# STM32L552xx register map
File version: 1.0
Registers are 32-bit, read-write, reset 0x0 unless marked. A register's access mark holds for its fields unless they carry their own. Offsets are from the block's base; [hi:lo] are bit positions; lines under a group give offsets from that group; {n}, {i} and the like mark numbered series.

## TSC — Touch Sensing Controller (TSC)
Base 0x40024000
Same registers: TSC_S 0x50024000
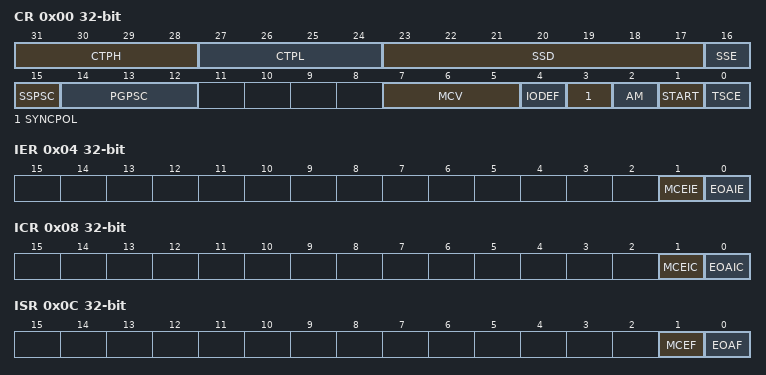
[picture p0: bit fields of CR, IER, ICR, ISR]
0x00 CR — TSC control register
  [31:28] CTPH — CTPH[3:0] bits (Charge Transfer pulse high)
  [27:24] CTPL — CTPL[3:0] bits (Charge Transfer pulse low)
  [23:17] SSD — SSD[6:0] bits (Spread Spectrum Deviation)
  [16] SSE — Spread Spectrum Enable
  [15] SSPSC — Spread Spectrum Prescaler
  [14:12] PGPSC — PGPSC[2:0] bits (Pulse Generator Prescaler)
  [7:5] MCV — MCV[2:0] bits (Max Count Value)
  [4] IODEF — IO default mode
  [3] SYNCPOL — Synchronization pin polarity
  [2] AM — Acquisition mode
  [1] START — Start acquisition
  [0] TSCE — Touch sensing controller enable
0x04 IER — TSC interrupt enable register
  [1] MCEIE — Max count error interrupt enable
  [0] EOAIE — End of acquisition interrupt enable
0x08 ICR — TSC interrupt clear register
  [1] MCEIC — Max count error interrupt clear
  [0] EOAIC — End of acquisition interrupt clear
0x0C ISR — TSC interrupt status register
  [1] MCEF — Max count error flag
  [0] EOAF — End of acquisition flag
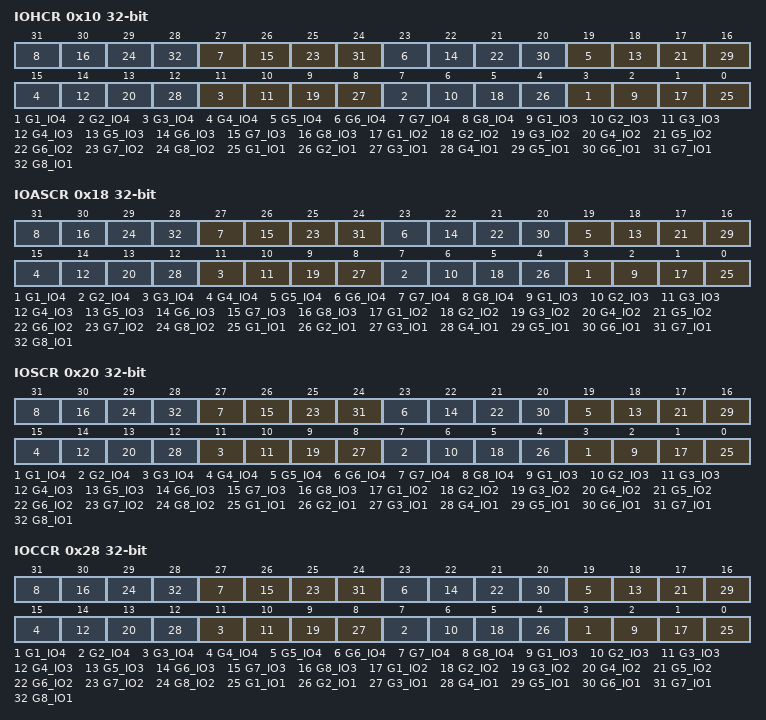
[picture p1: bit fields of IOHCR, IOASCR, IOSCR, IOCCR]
0x10 IOHCR — TSC I/O hysteresis control register
  [4n-1] G{n}_IO4 (n=1..8) — GROUP{n}_IO4 schmitt trigger hysteresis mode
  [4n-2] G{n}_IO3 (n=1..8) — GROUP{n}_IO3 schmitt trigger hysteresis mode
  [4n-3] G{n}_IO2 (n=1..8) — GROUP{n}_IO2 schmitt trigger hysteresis mode
  [4n-4] G{n}_IO1 (n=1..8) — GROUP{n}_IO1 schmitt trigger hysteresis mode
0x18 IOASCR — TSC I/O analog switch control register
  [4n-1] G{n}_IO4 (n=1..8) — GROUP{n}_IO4 analog switch enable
  [4n-2] G{n}_IO3 (n=1..8) — GROUP{n}_IO3 analog switch enable
  [4n-3] G{n}_IO2 (n=1..8) — GROUP{n}_IO2 analog switch enable
  [4n-4] G{n}_IO1 (n=1..8) — GROUP{n}_IO1 analog switch enable
0x20 IOSCR — TSC I/O sampling control register
  [4n-1] G{n}_IO4 (n=1..8) — GROUP{n}_IO4 sampling mode
  [4n-2] G{n}_IO3 (n=1..8) — GROUP{n}_IO3 sampling mode
  [4n-3] G{n}_IO2 (n=1..8) — GROUP{n}_IO2 sampling mode
  [4n-4] G{n}_IO1 (n=1..8) — GROUP{n}_IO1 sampling mode
0x28 IOCCR — TSC I/O channel control register
  [4n-1] G{n}_IO4 (n=1..8) — GROUP{n}_IO4 channel mode
  [4n-2] G{n}_IO3 (n=1..8) — GROUP{n}_IO3 channel mode
  [4n-3] G{n}_IO2 (n=1..8) — GROUP{n}_IO2 channel mode
  [4n-4] G{n}_IO1 (n=1..8) — GROUP{n}_IO1 channel mode
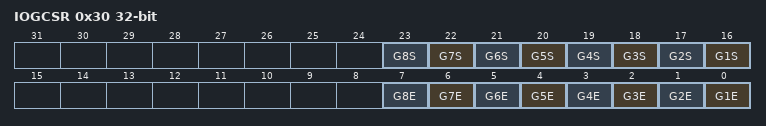
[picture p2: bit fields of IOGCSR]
0x30 IOGCSR — TSC I/O group control status register
  [n+15] G{n}S (n=1..8) — Analog IO GROUP{n} status
  [n-1] G{n}E (n=1..8) — Analog IO GROUP{n} enable
{0x30+4i} IOG{i}CR (i=1..8) — TSC I/O group x counter register
  [13:0] CNT — CNT[13:0] bits (Counter value)

## EXTI — Asynch Interrupt/Event Controller (EXTI)
Base 0x4002F400
Same registers: EXTI_S 0x5002F400
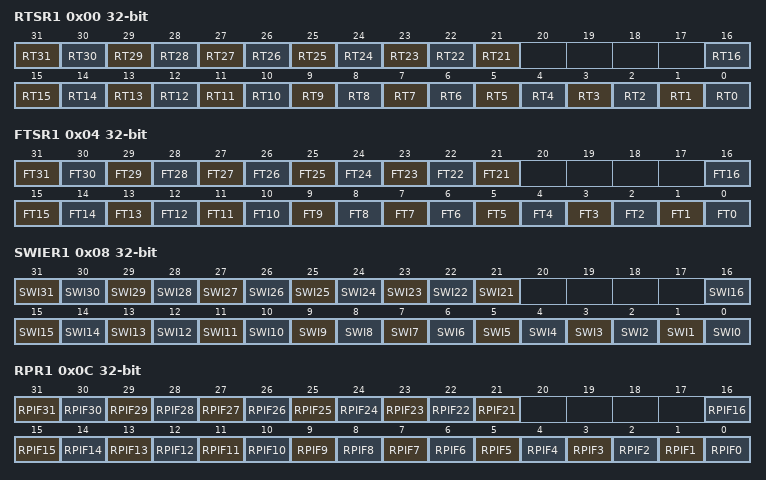
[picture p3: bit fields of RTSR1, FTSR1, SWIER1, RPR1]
0x00 RTSR1 — EXTI Rising Trigger Selection Register 1
  [n] RT{n} (n=21..31) — Rising trigger configuration for input line {n}
  [n] RT{n} (n=0..16) — Rising trigger configuration for input line {n}
0x04 FTSR1 — EXTI Falling Trigger Selection Register 1
  [n] FT{n} (n=21..31) — Falling trigger configuration for input line {n}
  [n] FT{n} (n=0..16) — Falling trigger configuration for input line {n}
0x08 SWIER1 — EXTI Software Interrupt event Register 1
  [n] SWI{n} (n=21..31) — Software Interrupt on line {n}
  [n] SWI{n} (n=0..16) — Software Interrupt on line {n}
0x0C RPR1 — EXTI Rising Pending Register 1
  [n] RPIF{n} (n=21..31) — Rising Pending Interrupt Flag on line {n}
  [n] RPIF{n} (n=0..16) — Rising Pending Interrupt Flag on line {n}
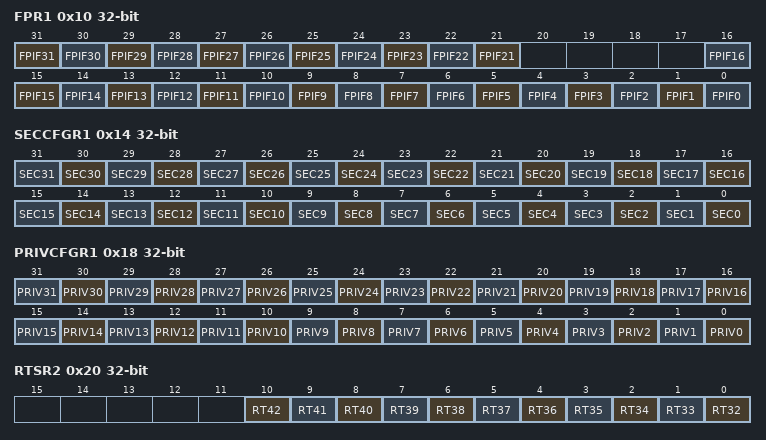
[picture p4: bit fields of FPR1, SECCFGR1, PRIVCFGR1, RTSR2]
0x10 FPR1 — EXTI Falling Pending Register 1
  [n] FPIF{n} (n=21..31) — Falling Pending Interrupt Flag on line {n}
  [n] FPIF{n} (n=0..16) — Falling Pending Interrupt Flag on line {n}
0x14 SECCFGR1 — EXTI Security Configuration Register 1
  [n] SEC{n} (n=0..31) — Security enable on Event input {n}
0x18 PRIVCFGR1 — EXTI Privilege Configuration Register 1
  [n] PRIV{n} (n=0..31) — Privilege enable on Event input {n}
0x20 RTSR2 — EXTI Rising Trigger Selection Register 2
  [n-32] RT{n} (n=32..42) — Rising trigger configuration for input line {n}
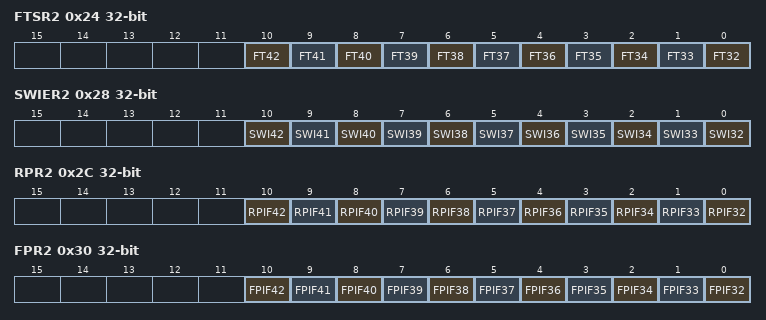
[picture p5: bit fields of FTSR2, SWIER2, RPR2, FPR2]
0x24 FTSR2 — EXTI Falling Trigger Selection Register 2
  [n-32] FT{n} (n=32..42) — Falling trigger configuration for input line {n}
0x28 SWIER2 — EXTI Software Interrupt event Register 2
  [n-32] SWI{n} (n=32..42) — Software Interrupt on line {n}
0x2C RPR2 — EXTI Rising Pending Register 2
  [n-32] RPIF{n} (n=32..42) — Rising Pending Interrupt Flag on line {n}
0x30 FPR2 — EXTI Falling Pending Register 2
  [n-32] FPIF{n} (n=32..42) — Falling Pending Interrupt Flag on line {n}
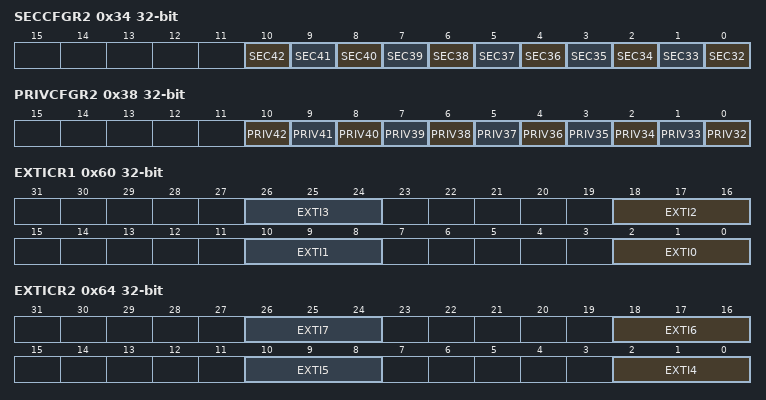
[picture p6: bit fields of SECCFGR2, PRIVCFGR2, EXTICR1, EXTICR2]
0x34 SECCFGR2 — EXTI Security Configuration Register 2
  [n-32] SEC{n} (n=32..42) — Security enable on Event input {n}
0x38 PRIVCFGR2 — EXTI Privilege Configuration Register 2
  [n-32] PRIV{n} (n=32..42) — Privilege enable on Event input {n}
0x60 EXTICR1 — EXTI External Interrupt Configuration Register, 0x60 -- 0x6C
  [8n+2:8n] EXTI{n} (n=0..3) — EXTI {n} configuration
0x64 EXTICR2 — EXTI External Interrupt Configuration Register, 0x60 -- 0x6C
  [8n-30:8n-32] EXTI{n} (n=4..7) — EXTI {n} configuration
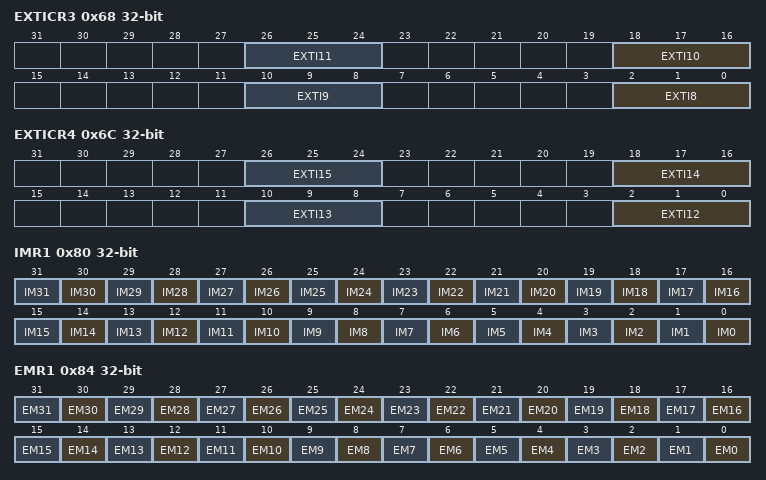
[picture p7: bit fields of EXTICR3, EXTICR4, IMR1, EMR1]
0x68 EXTICR3 — EXTI External Interrupt Configuration Register, 0x60 -- 0x6C
  [8n-62:8n-64] EXTI{n} (n=8..11) — EXTI {n} configuration
0x6C EXTICR4 — EXTI External Interrupt Configuration Register, 0x60 -- 0x6C
  [8n-94:8n-96] EXTI{n} (n=12..15) — EXTI {n} configuration
0x70 LOCKR — EXTI Lock Register
  [0] LOCK — Global security and privilege configuration lock
0x80 IMR1 — EXTI Interrupt Mask Register 1
  [n] IM{n} (n=0..31) — Interrupt Mask on line {n}
0x84 EMR1 — EXTI Event Mask Register 1
  [n] EM{n} (n=0..31) — Event Mask on line {n}
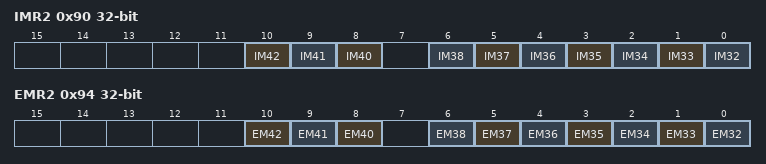
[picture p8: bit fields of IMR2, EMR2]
0x90 IMR2 — EXTI Interrupt Mask Register 2
  [10] IM42 — Interrupt Mask on line 42
  [9] IM41 — Interrupt Mask on line 41
  [8] IM40 — Interrupt Mask on line 40
  [n-32] IM{n} (n=32..38) — Interrupt Mask on line {n}
0x94 EMR2 — EXTI Event Mask Register 2
  [10] EM42 — Event Mask on line 42
  [9] EM41 — Event Mask on line 41
  [8] EM40 — Event Mask on line 40
  [n-32] EM{n} (n=32..38) — Event Mask on line {n}
